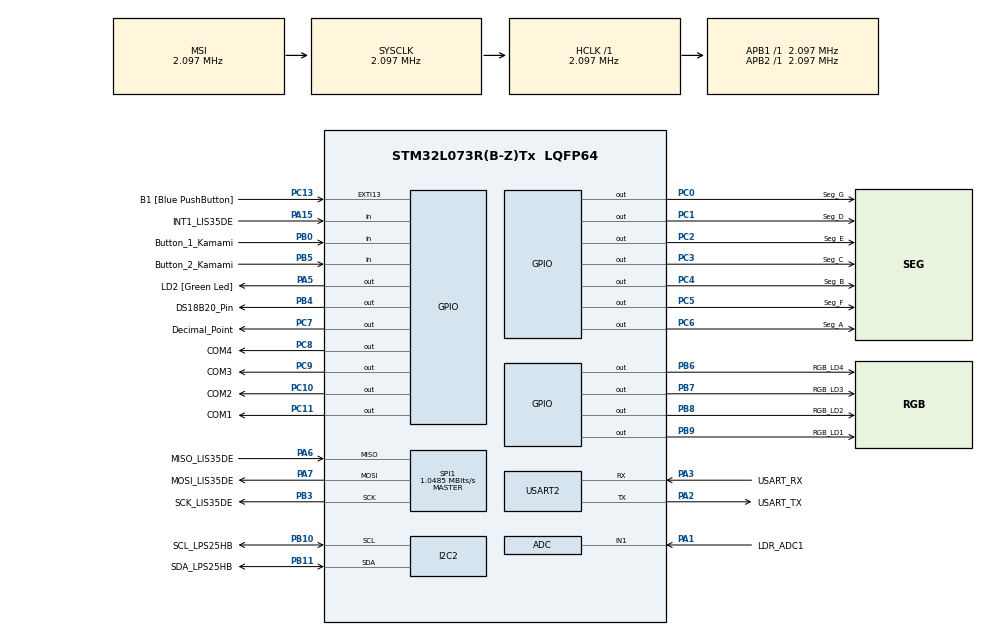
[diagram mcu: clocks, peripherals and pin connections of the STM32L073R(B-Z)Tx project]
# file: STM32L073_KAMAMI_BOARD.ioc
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Mcu.Family=STM32L0
Mcu.Name=STM32L073R(B-Z)Tx
Mcu.Package=LQFP64
NVIC.TIM2_IRQn=true\:0\:0\:false\:false\:true\:true\:true\:true
PA1.GPIO_Label=LDR_ADC1
PA1.Mode=IN1
PA1.Signal=ADC_IN1
PA13.GPIO_Label=TMS
PA13.Mode=Serial_Wire
PA13.Signal=SYS_SWDIO
PA14.GPIO_Label=TCK
PA14.Mode=Serial_Wire
PA14.Signal=SYS_SWCLK
PA15.GPIO_Label=INT1_LIS35DE
PA15.Signal=GPIO_Input
PA2.GPIO_Label=USART_TX
PA2.Mode=Asynchronous
PA2.Signal=USART2_TX
PA3.GPIO_Label=USART_RX
PA3.Mode=Asynchronous
PA3.Signal=USART2_RX
PA5.GPIO_Label=LD2 [Green Led]
PA5.Signal=GPIO_Output
PA6.GPIO_Label=MISO_LIS35DE
PA6.Mode=Full_Duplex_Master
PA6.Signal=SPI1_MISO
PA7.GPIO_Label=MOSI_LIS35DE
PA7.Mode=Full_Duplex_Master
PA7.Signal=SPI1_MOSI
PB0.GPIO_Label=Button_1_Kamami
PB0.Signal=GPIO_Input
PB10.GPIO_Label=SCL_LPS25HB
PB10.Mode=I2C
PB10.Signal=I2C2_SCL
PB11.GPIO_Label=SDA_LPS25HB
PB11.Mode=I2C
PB11.Signal=I2C2_SDA
PB3.GPIO_Label=SCK_LIS35DE
PB3.Mode=Full_Duplex_Master
PB3.Signal=SPI1_SCK
PB4.GPIO_Label=DS18B20_Pin
PB4.Signal=GPIO_Output
PB5.GPIO_Label=Button_2_Kamami
PB5.Signal=GPIO_Input
PB6.GPIO_Label=RGB_LD4
PB6.Signal=GPIO_Output
PB7.GPIO_Label=RGB_LD3
PB7.Signal=GPIO_Output
PB8.GPIO_Label=RGB_LD2
PB8.Signal=GPIO_Output
PB9.GPIO_Label=RGB_LD1
PB9.Signal=GPIO_Output
PC0.GPIO_Label=Seg_G
PC0.Signal=GPIO_Output
PC1.GPIO_Label=Seg_D
PC1.Signal=GPIO_Output
PC10.GPIO_Label=COM2
PC10.Signal=GPIO_Output
PC11.GPIO_Label=COM1
PC11.Signal=GPIO_Output
PC13.GPIO_Label=B1 [Blue PushButton]
PC13.GPIO_ModeDefaultEXTI=GPIO_MODE_IT_FALLING
PC13.Signal=GPXTI13
PC14-OSC32_IN.Mode=LSE-External-Oscillator
PC14-OSC32_IN.Signal=RCC_OSC32_IN
PC15-OSC32_OUT.Mode=LSE-External-Oscillator
PC15-OSC32_OUT.Signal=RCC_OSC32_OUT
PC2.GPIO_Label=Seg_E
PC2.Signal=GPIO_Output
PC3.GPIO_Label=Seg_C
PC3.Signal=GPIO_Output
PC4.GPIO_Label=Seg_B
PC4.Signal=GPIO_Output
PC5.GPIO_Label=Seg_F
PC5.Signal=GPIO_Output
PC6.GPIO_Label=Seg_A
PC6.Signal=GPIO_Output
PC7.GPIO_Label=Decimal_Point
PC7.Signal=GPIO_Output
PC8.GPIO_Label=COM4
PC8.Signal=GPIO_Output
PC9.GPIO_Label=COM3
PC9.Signal=GPIO_Output
PH0-OSC_IN.GPIO_Label=MCO
PH0-OSC_IN.Mode=HSE-External-Clock-Source
PH0-OSC_IN.Signal=RCC_OSC_IN
ProjectManager.HeapSize=0x200
ProjectManager.StackSize=0x400
ProjectManager.TargetToolchain=MDK-ARM V5.32
RCC.AHBFreq_Value=2097000
RCC.APB1Freq_Value=2097000
RCC.APB1TimFreq_Value=2097000
RCC.APB2Freq_Value=2097000
RCC.APB2TimFreq_Value=2097000
RCC.HCLKFreq_Value=2097000
RCC.HSE_VALUE=8000000
RCC.HSI16_VALUE=16000000
RCC.HSI48_VALUE=48000000
RCC.HSI_VALUE=16000000
RCC.MSI_VALUE=2097000
RCC.SYSCLKFreq_VALUE=2097000
RCC.VCOOutputFreq_Value=48000000
SPI1.CalculateBaudRate=1.0485 MBits/s
SPI1.Direction=SPI_DIRECTION_2LINES
SPI1.Mode=SPI_MODE_MASTER
SPI1.VirtualType=VM_MASTER
TIM2.Period=1000
TIM2.Prescaler=1000
USART2.VirtualMode-Asynchronous=VM_ASYNC
VP_TIM2_VS_ClockSourceINT.Mode=Internal
board=NUCLEO-L073RZ

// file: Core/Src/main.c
/* USER CODE BEGIN Header */
/**
  ******************************************************************************
  * @file           : main.c
  * @brief          : Main program body
  ******************************************************************************
  * @attention
  *
  * Copyright (c) 2022 STMicroelectronics.
  * All rights reserved.
  *
  * This software is licensed under terms that can be found in the LICENSE file
  * in the root directory of this software component.
  * If no LICENSE file comes with this software, it is provided AS-IS.
  *
  ******************************************************************************
  */
/* USER CODE END Header */
#include "main.h"

/* USER CODE BEGIN Includes */
#include "LPS25HB.h"
#include "4DIG_7SEG_DISPLAY.h"

/* USER CODE END Includes */

ADC_HandleTypeDef hadc;

I2C_HandleTypeDef hi2c2;

SPI_HandleTypeDef hspi1;

TIM_HandleTypeDef htim2;

UART_HandleTypeDef huart2;

/* USER CODE BEGIN PV */
float temperatura; // Temperatura

/* USER CODE END PV */

void SystemClock_Config(void);
static void MX_GPIO_Init(void);
static void MX_ADC_Init(void);
static void MX_I2C2_Init(void);
static void MX_SPI1_Init(void);
static void MX_USART2_UART_Init(void);
static void MX_TIM2_Init(void);

/* USER CODE BEGIN 0 */
// Override the weak call back function
void HAL_TIM_PeriodElapsedCallback(TIM_HandleTypeDef *htim) {
      if (htim->Instance == TIM2) {
              temperatura = LPS25HB_Measure_Temperature( &hi2c2);
      }
}
/* USER CODE END 0 */

int main(void)
{

  /* MCU Configuration--------------------------------------------------------*/

  /* Reset of all peripherals, Initializes the Flash interface and the Systick. */
  HAL_Init();

  /* Configure the system clock */
  SystemClock_Config();

  /* Initialize all configured peripherals */
  MX_GPIO_Init();
  MX_ADC_Init();
  MX_I2C2_Init();
  MX_SPI1_Init();
  MX_USART2_UART_Init();
  MX_TIM2_Init();
  /* USER CODE BEGIN 2 */
	HAL_TIM_Base_Start_IT(&htim2);
	LPS25HB_Initialise(&hi2c2);
  /* USER CODE END 2 */

  /* Infinite loop */
  /* USER CODE BEGIN WHILE */
  while (1) {
   SevenSegment_Display(temperatura);
    /* USER CODE END WHILE */

  }
}

void SystemClock_Config(void)
{
  RCC_OscInitTypeDef RCC_OscInitStruct = {0};
  RCC_ClkInitTypeDef RCC_ClkInitStruct = {0};
  RCC_PeriphCLKInitTypeDef PeriphClkInit = {0};

  /** Configure the main internal regulator output voltage
  */
  __HAL_PWR_VOLTAGESCALING_CONFIG(PWR_REGULATOR_VOLTAGE_SCALE1);

  /** Initializes the RCC Oscillators according to the specified parameters
  * in the RCC_OscInitTypeDef structure.
  */
  RCC_OscInitStruct.OscillatorType = RCC_OSCILLATORTYPE_MSI;
  RCC_OscInitStruct.MSIState = RCC_MSI_ON;
  RCC_OscInitStruct.MSICalibrationValue = 0;
  RCC_OscInitStruct.MSIClockRange = RCC_MSIRANGE_5;
  RCC_OscInitStruct.PLL.PLLState = RCC_PLL_NONE;
  if (HAL_RCC_OscConfig(&RCC_OscInitStruct) != HAL_OK)
  {
    Error_Handler();
  }

  /** Initializes the CPU, AHB and APB buses clocks
  */
  RCC_ClkInitStruct.ClockType = RCC_CLOCKTYPE_HCLK|RCC_CLOCKTYPE_SYSCLK
                              |RCC_CLOCKTYPE_PCLK1|RCC_CLOCKTYPE_PCLK2;
  RCC_ClkInitStruct.SYSCLKSource = RCC_SYSCLKSOURCE_MSI;
  RCC_ClkInitStruct.AHBCLKDivider = RCC_SYSCLK_DIV1;
  RCC_ClkInitStruct.APB1CLKDivider = RCC_HCLK_DIV1;
  RCC_ClkInitStruct.APB2CLKDivider = RCC_HCLK_DIV1;

  if (HAL_RCC_ClockConfig(&RCC_ClkInitStruct, FLASH_LATENCY_0) != HAL_OK)
  {
    Error_Handler();
  }
  PeriphClkInit.PeriphClockSelection = RCC_PERIPHCLK_USART2;
  PeriphClkInit.Usart2ClockSelection = RCC_USART2CLKSOURCE_PCLK1;
  if (HAL_RCCEx_PeriphCLKConfig(&PeriphClkInit) != HAL_OK)
  {
    Error_Handler();
  }
}

static void MX_ADC_Init(void)
{

  ADC_ChannelConfTypeDef sConfig = {0};

  /** Configure the global features of the ADC (Clock, Resolution, Data Alignment and number of conversion)
  */
  hadc.Instance = ADC1;
  hadc.Init.OversamplingMode = DISABLE;
  hadc.Init.ClockPrescaler = ADC_CLOCK_SYNC_PCLK_DIV1;
  hadc.Init.Resolution = ADC_RESOLUTION_12B;
  hadc.Init.SamplingTime = ADC_SAMPLETIME_1CYCLE_5;
  hadc.Init.ScanConvMode = ADC_SCAN_DIRECTION_FORWARD;
  hadc.Init.DataAlign = ADC_DATAALIGN_RIGHT;
  hadc.Init.ContinuousConvMode = DISABLE;
  hadc.Init.DiscontinuousConvMode = DISABLE;
  hadc.Init.ExternalTrigConvEdge = ADC_EXTERNALTRIGCONVEDGE_NONE;
  hadc.Init.ExternalTrigConv = ADC_SOFTWARE_START;
  hadc.Init.DMAContinuousRequests = DISABLE;
  hadc.Init.EOCSelection = ADC_EOC_SINGLE_CONV;
  hadc.Init.Overrun = ADC_OVR_DATA_PRESERVED;
  hadc.Init.LowPowerAutoWait = DISABLE;
  hadc.Init.LowPowerFrequencyMode = ENABLE;
  hadc.Init.LowPowerAutoPowerOff = DISABLE;
  if (HAL_ADC_Init(&hadc) != HAL_OK)
  {
    Error_Handler();
  }

  /** Configure for the selected ADC regular channel to be converted.
  */
  sConfig.Channel = ADC_CHANNEL_1;
  sConfig.Rank = ADC_RANK_CHANNEL_NUMBER;
  if (HAL_ADC_ConfigChannel(&hadc, &sConfig) != HAL_OK)
  {
    Error_Handler();
  }

}

static void MX_I2C2_Init(void)
{

  hi2c2.Instance = I2C2;
  hi2c2.Init.Timing = 0x00000708;
  hi2c2.Init.OwnAddress1 = 0;
  hi2c2.Init.AddressingMode = I2C_ADDRESSINGMODE_7BIT;
  hi2c2.Init.DualAddressMode = I2C_DUALADDRESS_DISABLE;
  hi2c2.Init.OwnAddress2 = 0;
  hi2c2.Init.OwnAddress2Masks = I2C_OA2_NOMASK;
  hi2c2.Init.GeneralCallMode = I2C_GENERALCALL_DISABLE;
  hi2c2.Init.NoStretchMode = I2C_NOSTRETCH_DISABLE;
  if (HAL_I2C_Init(&hi2c2) != HAL_OK)
  {
    Error_Handler();
  }

  /** Configure Analogue filter
  */
  if (HAL_I2CEx_ConfigAnalogFilter(&hi2c2, I2C_ANALOGFILTER_ENABLE) != HAL_OK)
  {
    Error_Handler();
  }

  /** Configure Digital filter
  */
  if (HAL_I2CEx_ConfigDigitalFilter(&hi2c2, 0) != HAL_OK)
  {
    Error_Handler();
  }

}

static void MX_SPI1_Init(void)
{

  /* SPI1 parameter configuration*/
  hspi1.Instance = SPI1;
  hspi1.Init.Mode = SPI_MODE_MASTER;
  hspi1.Init.Direction = SPI_DIRECTION_2LINES;
  hspi1.Init.DataSize = SPI_DATASIZE_8BIT;
  hspi1.Init.CLKPolarity = SPI_POLARITY_LOW;
  hspi1.Init.CLKPhase = SPI_PHASE_1EDGE;
  hspi1.Init.NSS = SPI_NSS_SOFT;
  hspi1.Init.BaudRatePrescaler = SPI_BAUDRATEPRESCALER_2;
  hspi1.Init.FirstBit = SPI_FIRSTBIT_MSB;
  hspi1.Init.TIMode = SPI_TIMODE_DISABLE;
  hspi1.Init.CRCCalculation = SPI_CRCCALCULATION_DISABLE;
  hspi1.Init.CRCPolynomial = 7;
  if (HAL_SPI_Init(&hspi1) != HAL_OK)
  {
    Error_Handler();
  }

}

static void MX_TIM2_Init(void)
{

  TIM_ClockConfigTypeDef sClockSourceConfig = {0};
  TIM_MasterConfigTypeDef sMasterConfig = {0};

  htim2.Instance = TIM2;
  htim2.Init.Prescaler = 2000;
  htim2.Init.CounterMode = TIM_COUNTERMODE_UP;
  htim2.Init.Period = 1000;
  htim2.Init.ClockDivision = TIM_CLOCKDIVISION_DIV1;
  htim2.Init.AutoReloadPreload = TIM_AUTORELOAD_PRELOAD_DISABLE;
  if (HAL_TIM_Base_Init(&htim2) != HAL_OK)
  {
    Error_Handler();
  }
  sClockSourceConfig.ClockSource = TIM_CLOCKSOURCE_INTERNAL;
  if (HAL_TIM_ConfigClockSource(&htim2, &sClockSourceConfig) != HAL_OK)
  {
    Error_Handler();
  }
  sMasterConfig.MasterOutputTrigger = TIM_TRGO_RESET;
  sMasterConfig.MasterSlaveMode = TIM_MASTERSLAVEMODE_DISABLE;
  if (HAL_TIMEx_MasterConfigSynchronization(&htim2, &sMasterConfig) != HAL_OK)
  {
    Error_Handler();
  }

}

static void MX_USART2_UART_Init(void)
{

  huart2.Instance = USART2;
  huart2.Init.BaudRate = 115200;
  huart2.Init.WordLength = UART_WORDLENGTH_8B;
  huart2.Init.StopBits = UART_STOPBITS_1;
  huart2.Init.Parity = UART_PARITY_NONE;
  huart2.Init.Mode = UART_MODE_TX_RX;
  huart2.Init.HwFlowCtl = UART_HWCONTROL_NONE;
  huart2.Init.OverSampling = UART_OVERSAMPLING_16;
  huart2.Init.OneBitSampling = UART_ONE_BIT_SAMPLE_DISABLE;
  huart2.AdvancedInit.AdvFeatureInit = UART_ADVFEATURE_NO_INIT;
  if (HAL_UART_Init(&huart2) != HAL_OK)
  {
    Error_Handler();
  }

}

static void MX_GPIO_Init(void)
{
  GPIO_InitTypeDef GPIO_InitStruct = {0};

  /* GPIO Ports Clock Enable */
  __HAL_RCC_GPIOC_CLK_ENABLE();
  __HAL_RCC_GPIOH_CLK_ENABLE();
  __HAL_RCC_GPIOA_CLK_ENABLE();
  __HAL_RCC_GPIOB_CLK_ENABLE();

  /*Configure GPIO pin Output Level */
  HAL_GPIO_WritePin(GPIOC, Seg_G_Pin|Seg_D_Pin|Seg_E_Pin|Seg_C_Pin
                          |Seg_B_Pin|Seg_F_Pin|Seg_A_Pin|Decimal_Point_Pin
                          |COM4_Pin|COM3_Pin|COM2_Pin|COM1_Pin, GPIO_PIN_RESET);

  /*Configure GPIO pin Output Level */
  HAL_GPIO_WritePin(LD2_GPIO_Port, LD2_Pin, GPIO_PIN_RESET);

  /*Configure GPIO pin Output Level */
  HAL_GPIO_WritePin(GPIOB, DS18B20_Pin_Pin|RGB_LD4_Pin|RGB_LD3_Pin|RGB_LD2_Pin
                          |RGB_LD1_Pin, GPIO_PIN_RESET);

  /*Configure GPIO pin : B1_Pin */
  GPIO_InitStruct.Pin = B1_Pin;
  GPIO_InitStruct.Mode = GPIO_MODE_IT_FALLING;
  GPIO_InitStruct.Pull = GPIO_NOPULL;
  HAL_GPIO_Init(B1_GPIO_Port, &GPIO_InitStruct);

  /*Configure GPIO pins : Seg_G_Pin Seg_D_Pin Seg_E_Pin Seg_C_Pin
                           Seg_B_Pin Seg_F_Pin Seg_A_Pin Decimal_Point_Pin
                           COM4_Pin COM3_Pin COM2_Pin COM1_Pin */
  GPIO_InitStruct.Pin = Seg_G_Pin|Seg_D_Pin|Seg_E_Pin|Seg_C_Pin
                          |Seg_B_Pin|Seg_F_Pin|Seg_A_Pin|Decimal_Point_Pin
                          |COM4_Pin|COM3_Pin|COM2_Pin|COM1_Pin;
  GPIO_InitStruct.Mode = GPIO_MODE_OUTPUT_PP;
  GPIO_InitStruct.Pull = GPIO_NOPULL;
  GPIO_InitStruct.Speed = GPIO_SPEED_FREQ_LOW;
  HAL_GPIO_Init(GPIOC, &GPIO_InitStruct);

  /*Configure GPIO pin : LD2_Pin */
  GPIO_InitStruct.Pin = LD2_Pin;
  GPIO_InitStruct.Mode = GPIO_MODE_OUTPUT_PP;
  GPIO_InitStruct.Pull = GPIO_NOPULL;
  GPIO_InitStruct.Speed = GPIO_SPEED_FREQ_LOW;
  HAL_GPIO_Init(LD2_GPIO_Port, &GPIO_InitStruct);

  /*Configure GPIO pins : Button_1_Kamami_Pin Button_2_Kamami_Pin */
  GPIO_InitStruct.Pin = Button_1_Kamami_Pin|Button_2_Kamami_Pin;
  GPIO_InitStruct.Mode = GPIO_MODE_INPUT;
  GPIO_InitStruct.Pull = GPIO_NOPULL;
  HAL_GPIO_Init(GPIOB, &GPIO_InitStruct);

  /*Configure GPIO pin : INT1_LIS35DE_Pin */
  GPIO_InitStruct.Pin = INT1_LIS35DE_Pin;
  GPIO_InitStruct.Mode = GPIO_MODE_INPUT;
  GPIO_InitStruct.Pull = GPIO_NOPULL;
  HAL_GPIO_Init(INT1_LIS35DE_GPIO_Port, &GPIO_InitStruct);

  /*Configure GPIO pins : DS18B20_Pin_Pin RGB_LD4_Pin RGB_LD3_Pin RGB_LD2_Pin
                           RGB_LD1_Pin */
  GPIO_InitStruct.Pin = DS18B20_Pin_Pin|RGB_LD4_Pin|RGB_LD3_Pin|RGB_LD2_Pin
                          |RGB_LD1_Pin;
  GPIO_InitStruct.Mode = GPIO_MODE_OUTPUT_PP;
  GPIO_InitStruct.Pull = GPIO_NOPULL;
  GPIO_InitStruct.Speed = GPIO_SPEED_FREQ_LOW;
  HAL_GPIO_Init(GPIOB, &GPIO_InitStruct);

}

void Error_Handler(void)
{
  __disable_irq();
  while (1)
  {
  }
}
